# nrf7140_sysctrl register map
Vendor: Nordic Semiconductor; Series: nRF71; File version: 1
Registers are 32-bit, read-write, reset 0x0 unless marked. A register's access mark holds for its fields unless they carry their own. Offsets are from the block's base; [hi:lo] are bit positions; lines under a group give offsets from that group; {n}, {i} and the like mark numbered series; 'fields as' and 'values as' point back to an identical list.

## GLOBAL_STMDATA — System Trace Macrocell data buffer
Base 0xA0000000
{0x0+0x1000000*i} DOMAIN[{i}] (i=0..15) group — Unspecified
  {0x0+j} DATA[{j}] (j=0..16777215) 8-bit — Description collection: STM extended stimulus port data buffer area for domain n. NonSecure writes to this region generates trace packets with id n+96. Secure writes to this region generates trace packets with id n+32.

## GLOBAL_TDDCONF — TDDCONF
Base 0xBF001000
0x400 SYSPWRUPREQ — System power-up request
  [0] ACTIVE — Activate power-up request
    0=NotActive (Power-up request not active); 1=Active (Power-up request active)
0x404 DBGPWRUPREQ — Debug power-up request
  fields as SYSPWRUPREQ
0x408 TRACEPORTSPEED — Trace port trace clock speed
  [1:0] SPEED — Trace clock speed
    0=Speed80MHz; 1=Speed40MHz; 2=Speed20MHz; 3=Speed10MHz
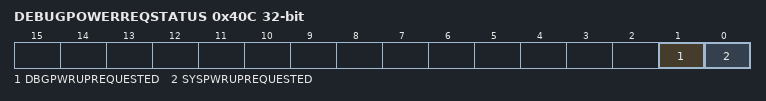
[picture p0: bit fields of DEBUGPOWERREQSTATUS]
0x40C DEBUGPOWERREQSTATUS ro — Combined effective system status of both SWJ-DP and TDDCONF registers originated power requests
  [1] DBGPWRUPREQUESTED — Debug domain powerup request status
    0=NoPowerReq (Power not requested); 1=Power requested
  [0] SYSPWRUPREQUESTED — System powerup request status
    0=NoPowerReq (Power not requested); 1=Power requested

## PCGCM200 — PCGC Master 0
Base 0xBF006000
Same registers: GLOBAL_PCGCM300 0x4900F000, GLOBAL_PCGCM310 0x4901F000, PCGCM110 0x5F08F000, PCGCM120 0x5F8CF000, PCGCM121 0x5F8ED000, PCGCM130 0x5F93D000, PCGCM131 0x5F93F000, PCGCM132 0x5F94F000, PCGCM133 0x5F98F000, PCGCM134 0x5F99F000, PCGCM135 0x5F9AF000, PCGCM136 0x5F9BF000, PCGCM137 0x5F9CF000, PCGCM138 0x5F9DF000, PCGCM210 0xBF013000
{0xE0+4i} SETPWRCONTHRESHOLDBASE[{i}] (i=0..2) — Description collection: Set power consumption threshold base for power source / regulator n
  [3:0] SETPWRCONTHRESHOLDBASE
0xC00 UNLOCKBACKDOORS
  [15:0] UNLOCKBACKDOORS — Write: 0x00009375 to lock/unlock backdoors Read: 0x00000001 if backdoors is enabled Read: 0x00000000 if backdoors is disabled
0xC04 ENABLEPOWERREGFORCE
  [2:0] ENABLEPOWERREGFORCE
0xC08 POWERREGFORCE — Force reg
  [2:0] POWERREGFORCEREG
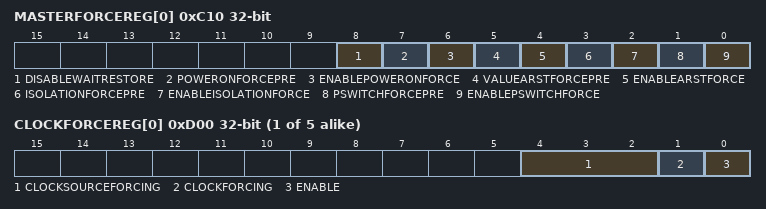
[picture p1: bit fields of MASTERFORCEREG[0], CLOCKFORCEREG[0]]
{0xC10+4i} MASTERFORCEREG[{i}] (i=0..0) — Description collection: Force reg
  [8] DISABLEWAITRESTORE — Turn off waiting for arst deactivation before retention restore
    1=Disable (Turn off waiting for arst deactivation before retention restore); 0=Enable (Wait for arst deactivation before retention restore)
  [7] POWERONFORCEPRE
  [6] ENABLEPOWERONFORCE
  [5] VALUEARSTFORCEPRE
  [4] ENABLEARSTFORCE
  [3] ISOLATIONFORCEPRE
  [2] ENABLEISOLATIONFORCE
  [1] PSWITCHFORCEPRE
  [0] ENABLEPSWITCHFORCE
{0xD00+4i} CLOCKFORCEREG[{i}] (i=0..4) — Description collection: Force clock n
  [4:2] CLOCKSOURCEFORCING
  [1] CLOCKFORCING
  [0] ENABLE — Enable clock forcing

## PCGCS200 — PCGCSlave 0
Base 0xBF011000
Same registers: PCGCS110 0x5F08E000, PCGCS120 0x5F8EA000, PCGCS121 0x5F8EB000, PCGCS122 0x5F8EC000, PCGCS130 0x5F90E000, PCGCS131 0x5F93C000, PCGCS132 0x5F94E000, PCGCS133 0x5F98E000, PCGCS134 0x5F99E000, PCGCS135 0x5F9AE000, PCGCS136 0x5F9BE000, PCGCS137 0x5F9CE000, PCGCS138 0x5F9DE000
{0xC00+4i} PENALTY[{i}] (i=0..1) reset 0xFFFFFFFC — Description collection: Penalty level for power/clock pair n. When FULL_PCP_ZERO feature is not supported, PENALTY[0] address overlaps the PENALTY0 address and register description for PENALTY[0] is not valid.
  [1:0] PENALTY — Penalty level
0xC00 PENALTY0 (alternate view of PENALTY[*]) — Penalty level for power/clock pair 0. The register description is valid only when FULL_PCP_ZERO feature is not supported
  [1:0] PENALTY ro — Penalty level
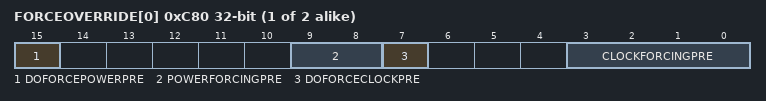
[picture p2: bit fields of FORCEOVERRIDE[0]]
{0xC80+4i} FORCEOVERRIDE[{i}] (i=0..1) — Description collection: Force override of power/clock pair n.
  [15] DOFORCEPOWERPRE, [9:8] POWERFORCINGPRE, [7] DOFORCECLOCKPRE, [3:0] CLOCKFORCINGPRE

## GLOBAL_PCGCSBUS — PCGCSlave
Base 0x4900CF00; alternate view of GLOBAL_GFXPLLPM
Registers as PCGCS200.
